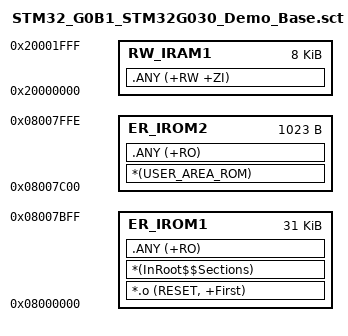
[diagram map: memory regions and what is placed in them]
; *************************************************************
; *** Scatter-Loading Description File generated by uVision ***
; *************************************************************

LR_IROM1 0x08000000 0x00007C00  {    ; load region size_region
  ER_IROM1 0x08000000 0x00007C00  {  ; load address = execution address
   *.o (RESET, +First)
   *(InRoot$$Sections)
   .ANY (+RO)
  }
  RW_IRAM1 0x20000000 0x00002000  {  ; RW data
   .ANY (+RW +ZI)
  }
}


LR_IROM2 0x08007C00 0x000003FF  {    ; load region size_region
  ER_IROM2 0x08007C00 0x000003FF  {  ; load address = execution address
   *(USER_AREA_ROM)
   .ANY (+RO)
  }
 }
